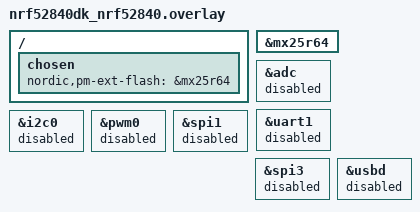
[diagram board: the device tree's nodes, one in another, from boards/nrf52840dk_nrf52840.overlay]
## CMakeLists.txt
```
#
# Copyright (c) 2021 Nordic Semiconductor ASA
#
# SPDX-License-Identifier: LicenseRef-Nordic-5-Clause
#

cmake_minimum_required(VERSION 3.20.0)

find_package(Zephyr REQUIRED HINTS $ENV{ZEPHYR_BASE})
project(matter-lock)

# NORDIC SDK APP START

# Include Data Model and ZAP utils
include(${ZEPHYR_NCS_MATTER_MODULE_DIR}/cmake/sample.cmake)

ncs_get_zap_parent_dir(ZAP_PARENT_DIR)
zephyr_include_directories(${ZAP_PARENT_DIR})

target_include_directories(app PRIVATE
  src
)

target_sources(app PRIVATE
  src/app_task.cpp
  src/bolt_lock_manager.cpp
  src/main.cpp
  src/zcl_callbacks.cpp
)

# Do not treat warnings as errors while the variable may be uninitialized for this sample data model.
# In the door-lock-server implementation, there is a warning that the C++ "optional"
# variable may be uninitialized, but actually, it is wrongly interpreted by the Zephyr toolchain.
target_compile_options(matter-data-model PRIVATE -Wno-error=maybe-uninitialized)

# Without the OpenThread shell and logging, nothing references the OpenThread API objects before
# libCHIP.a is scanned, so symbols used only by Matter's Thread platform stay unresolved. Link the
# OpenThread library again after Matter, so that the linker can resolve them.
if(CONFIG_OPENTHREAD_SOURCES)
  if(CONFIG_OPENTHREAD_FTD)
    set(ot_core_lib openthread-ftd)
  else()
    set(ot_core_lib openthread-mtd)
  endif()
  target_link_libraries(chip INTERFACE
    -Wl,--start-group
    $<TARGET_FILE:${ot_core_lib}>
    -Wl,--end-group
  )
endif()

ncs_configure_data_model()

# NORDIC SDK APP END
```

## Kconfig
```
#
# Copyright (c) 2021 Nordic Semiconductor
#
# SPDX-License-Identifier: LicenseRef-Nordic-5-Clause
#

mainmenu "Matter Lock sample application"

config LOCK_PASS_CREDENTIALS_TO_SET_LOCK_STATE
	bool "Pass used credentials when setting the lock state"
	help
	  This option should stay disabled until TC-DRLK-2.3 is fixed.
	  Related issue: https://github.com/project-chip/connectedhomeip/issues/38222

config STATE_LEDS
	bool "Use LEDs to indicate the device state"
	default y
	help
	  Use LEDs to render the current state of the device such as the progress of commissioning of
	  the device into a network or the factory reset initiation. Note that setting this option to
	  'n' does not disable the LED indicating the state of the simulated bolt.
# Sample configuration used for Thread networking
if OPENTHREAD

choice OPENTHREAD_NORDIC_LIBRARY_CONFIGURATION
	default OPENTHREAD_NORDIC_LIBRARY_MTD
endchoice

choice OPENTHREAD_DEVICE_TYPE
	default OPENTHREAD_MTD
endchoice

choice OPENTHREAD_IMPLEMENTATION
	default OPENTHREAD_SOURCES
endchoice

config CHIP_ENABLE_ICD_SUPPORT
	default y

# Reduce Thread TX output power to 0 dBm for SED device
config OPENTHREAD_DEFAULT_TX_POWER
	default 0

endif # OPENTHREAD

# Increase the storage capacity if the schedules are enabled with secure storage
# This also implies increasing of the OT and Matter stacks because some operations
# performed during commissioning seem to allocate stack buffers based on the
# maximum possible secure asset size.
if DOOR_LOCK_MATTER_ACCESS_SCHEDULES && MATTER_SECURE_STORAGE_BACKEND

config MATTER_SECURE_STORAGE_MAX_ENTRY_NUMBER
	default 128

config TRUSTED_STORAGE_BACKEND_AEAD_MAX_DATA_SIZE
	default 3072

config OPENTHREAD_THREAD_STACK_SIZE
	default 7168

config CHIP_TASK_STACK_SIZE
	default 10240

config MAIN_STACK_SIZE
	default 7168

endif

configdefault HW_UNIQUE_KEY_WRITE_ON_CRYPTO_INIT
	default y

# Keep entries stored by the deprecated Trusted Storage library readable
configdefault SECURE_STORAGE_TRUSTED_STORAGE_COMPATIBILITY
	default y

# The ZMS store implementation supports only 30-bit UIDs
choice SECURE_STORAGE_ITS_STORE_IMPLEMENTATION
	default SECURE_STORAGE_ITS_STORE_IMPLEMENTATION_SETTINGS
endchoice

# Workaround for KRKNWK-20979.
# We must use BT multirole for pairing to work after Matter commissioning.
# TODO: Remove this once the issue is fixed.
choice BT_LL_SOFTDEVICE_VARIANT
	default BT_LL_SOFTDEVICE_MULTIROLE if SOC_SERIES_NRF54L && BT_SMP
endchoice

configdefault CHIP_DEVICE_PRODUCT_FINISH
    default "matte"

configdefault CHIP_DEVICE_PRODUCT_COLOR
    default "navy"

source "$(ZEPHYR_CONNECTEDHOMEIP_MODULE_DIR)/config/nrfconnect/chip-module/Kconfig.features"
source "$(ZEPHYR_CONNECTEDHOMEIP_MODULE_DIR)/config/nrfconnect/chip-module/Kconfig.defaults"
source "Kconfig.zephyr"
```

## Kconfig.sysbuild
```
#
# Copyright (c) 2023 Nordic Semiconductor ASA
#
# SPDX-License-Identifier: LicenseRef-Nordic-5-Clause
#

#### Radio core selection
config NRF_DEFAULT_IPC_RADIO
	default y

# Enable IEEE802.15.4 serialization to network core
# This config automatically pulls in the `overlay-802154.conf` in the ipc_radio image
config NETCORE_IPC_RADIO_IEEE802154
	default y

# Enable Bluetooth serialization to network core
# This config automatically pulls in the `overlay-bt_hci_ipc.conf` in the ipc_radio image
config NETCORE_IPC_RADIO_BT_HCI_IPC
	default y

#### Matter OTA
config MATTER_ADD_ON_OTA
	default n if BOARD_NRF7120DK_NRF7120_CPUAPP
	default y

#### Bootloader
choice BOOTLOADER
	default BOOTLOADER_MCUBOOT if !BOARD_NRF7120DK_NRF7120_CPUAPP
endchoice

if BOOTLOADER_MCUBOOT

#### DFU multi-image support
config DFU_MULTI_IMAGE_PACKAGE_BUILD
	default y

config DFU_MULTI_IMAGE_PACKAGE_APP
	default y

#### DFU network core configuration
if SOC_SERIES_NRF53

choice MCUBOOT_MODE
	default MCUBOOT_MODE_OVERWRITE_ONLY
endchoice

choice BOOT_SIGNATURE_TYPE
	default BOOT_SIGNATURE_TYPE_RSA
endchoice

config SECURE_BOOT_NETCORE
	default y

config NETCORE_APP_UPDATE
	default y

config DFU_MULTI_IMAGE_PACKAGE_NET
	default y

endif # SOC_SERIES_NRF53

endif # BOOTLOADER_MCUBOOT

#### Enable generating factory data
config MATTER_ADD_ON_FACTORY_DATA_GENERATE
	default y

source "share/sysbuild/Kconfig"
```

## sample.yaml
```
sample:
  description: Matter Lock example
  name: Matter Lock
common:
  tags:
    - sysbuild
    - ci_samples_matter
tests:
  sample.matter.lock.debug:
    sysbuild: true
    build_only: true
    tags:
      - dfu_supported
    integration_platforms:
      - nrf54l15dk/nrf54l15/cpuapp
    platform_allow:
      - nrf5340dk/nrf5340/cpuapp
      - nrf54l15dk/nrf54l15/cpuapp
      - nrf54lm20dk/nrf54lm20b/cpuapp
  sample.matter.lock.nrf7120.debug:
    sysbuild: true
    build_only: true
    integration_platforms:
      - nrf7120dk/nrf7120/cpuapp
    platform_allow:
      - nrf7120dk/nrf7120/cpuapp
  sample.matter.lock.release:
    sysbuild: true
    build_only: true
    tags:
      - dfu_supported
    extra_args:
      - FILE_SUFFIX=release
    integration_platforms:
      - nrf5340dk/nrf5340/cpuapp
      - nrf54lm20dk/nrf54lm20b/cpuapp
    platform_allow:
      - nrf5340dk/nrf5340/cpuapp
      - nrf54l15dk/nrf54l15/cpuapp
      - nrf54lm20dk/nrf54lm20b/cpuapp
  sample.matter.lock.smp_dfu:
    sysbuild: true
    build_only: true
    tags:
      - dfu_supported
    extra_args:
      - matter-door-lock-app_SNIPPET="dfu_smp"
    integration_platforms:
      - nrf5340dk/nrf5340/cpuapp
      - nrf54l15dk/nrf54l15/cpuapp
      - nrf54lm20dk/nrf54lm20b/cpuapp
    platform_allow:
      - nrf5340dk/nrf5340/cpuapp
      - nrf54l15dk/nrf54l15/cpuapp
      - nrf54lm20dk/nrf54lm20b/cpuapp
  sample.matter.lock.nus:
    sysbuild: true
    build_only: true
    tags:
      - dfu_supported
    extra_args:
      - matter-door-lock-app_SNIPPET=bt_nus
      - CONFIG_DOOR_LOCK_BLE_MANAGER_AUTH_APP_PASSKEY=112233
    integration_platforms:
      - nrf5340dk/nrf5340/cpuapp
    platform_allow:
      - nrf5340dk/nrf5340/cpuapp
      - nrf54l15dk/nrf54l15/cpuapp
      - nrf54lm20dk/nrf54lm20b/cpuapp
  sample.matter.lock.schedules:
    sysbuild: true
    build_only: true
    tags:
      - dfu_supported
    extra_args:
      - EXTRA_CONF_FILE=schedules.conf
    integration_platforms:
      - nrf5340dk/nrf5340/cpuapp
    platform_allow:
      - nrf5340dk/nrf5340/cpuapp
  sample.matter.lock.release.power_consumption:
    sysbuild: true
    build_only: true
    extra_args:
      - FILE_SUFFIX=release
      - CONFIG_MATTER_LEDS=n
      - CONFIG_MATTER_WATCHDOG=n
      - CONFIG_CHIP_ENABLE_PAIRING_AUTOSTART=y
    integration_platforms:
      - nrf5340dk/nrf5340/cpuapp
    platform_allow:
      - nrf5340dk/nrf5340/cpuapp
      - nrf54l15dk/nrf54l15/cpuapp
      - nrf54lm20dk/nrf54lm20b/cpuapp
```

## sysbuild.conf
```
#
# Copyright (c) 2024 Nordic Semiconductor
#
# SPDX-License-Identifier: LicenseRef-Nordic-5-Clause
#

SB_CONFIG_MATTER_ADD_ON=y

SB_CONFIG_MATTER_ADD_ON_FACTORY_DATA_MERGE_WITH_FIRMWARE=y

SB_CONFIG_MERGED_HEX_FILES=y
```

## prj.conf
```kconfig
#
# Copyright (c) 2022 Nordic Semiconductor ASA
#
# SPDX-License-Identifier: LicenseRef-Nordic-5-Clause
#

# This sample uses Kconfig.defaults to set options common for all
# samples. This file should contain only options specific for this sample
# or overrides of default values.

# Enable CHIP
CONFIG_CHIP=y
CONFIG_CHIP_DEVICE_PRODUCT_NAME="Matter Door Lock"

# Configure ZAP file name
CONFIG_MATTER_ZAP_FILE_PATH="${APPLICATION_CONFIG_DIR}/src/default_zap/lock.zap"

# 32774 == 0x8006 (example lock-app)
CONFIG_CHIP_DEVICE_PRODUCT_ID=32774
CONFIG_STD_CPP17=y

# Enable Matter extended announcement and increase duration to 1 hour.
CONFIG_CHIP_BLE_EXT_ADVERTISING=y
CONFIG_CHIP_BLE_ADVERTISING_DURATION=60

# Add support for LEDs and buttons on Nordic development kits
CONFIG_DK_LIBRARY=y

# Bluetooth Low Energy configuration
CONFIG_BT_DEVICE_NAME="MatterLock"

# Suspend devices when the CPU goes into sleep
CONFIG_PM_DEVICE=y
CONFIG_PM_DEVICE_RUNTIME=y
CONFIG_CHIP_QSPI_NOR_POWER_MANAGEMENT_SUPPORT=n

# Other settings
CONFIG_THREAD_NAME=y
CONFIG_MPU_STACK_GUARD=y
CONFIG_RESET_ON_FATAL_ERROR=n
CONFIG_CHIP_LIB_SHELL=y
CONFIG_MATTER_TEST_SHELL=y

# Reduce application size
CONFIG_USE_SEGGER_RTT=n
CONFIG_MATTER_LOG_LEVEL_INF=y
CONFIG_CHIP_APP_LOG_LEVEL=3

# Enable Factory Data feature
CONFIG_CHIP_FACTORY_DATA=y
CONFIG_CHIP_FACTORY_DATA_BUILD=y

# Enable Matter Access module
CONFIG_DOOR_LOCK_MATTER_ACCESS=y
CONFIG_DOOR_LOCK_MATTER_ACCESS_CREDENTIAL_TYPES_PIN=y

CONFIG_MATTER_ZAP_GENERATION_STATIC=y
CONFIG_SECURE_STORAGE=n
```

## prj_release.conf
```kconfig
#
# Copyright (c) 2022 Nordic Semiconductor ASA
#
# SPDX-License-Identifier: LicenseRef-Nordic-5-Clause
#

# This sample uses Kconfig.defaults to set options common for all
# samples. This file should contain only options specific for this sample
# or overrides of default values.

# Enable CHIP
CONFIG_CHIP=y
CONFIG_CHIP_DEVICE_PRODUCT_NAME="Matter Door Lock"

# Configure ZAP file name
CONFIG_MATTER_ZAP_FILE_PATH="${APPLICATION_CONFIG_DIR}/src/default_zap/lock.zap"

# 32774 == 0x8006 (example lock-app)
CONFIG_CHIP_DEVICE_PRODUCT_ID=32774
CONFIG_STD_CPP17=y

# Enable Matter extended announcement and increase duration to 1 hour.
CONFIG_CHIP_BLE_EXT_ADVERTISING=y
CONFIG_CHIP_BLE_ADVERTISING_DURATION=60

# Add support for LEDs and buttons on Nordic development kits
CONFIG_DK_LIBRARY=y

# Bluetooth Low Energy configuration
CONFIG_BT_DEVICE_NAME="MatterLock"

# Suspend devices when the CPU goes into sleep
CONFIG_PM_DEVICE=y

# Enable system reset on fatal error
CONFIG_RESET_ON_FATAL_ERROR=y

# Try to disable unused RAM blocks to reduce power consumption
CONFIG_RAM_POWER_DOWN_LIBRARY=y

# Disable all debug features
CONFIG_USE_SEGGER_RTT=n
CONFIG_SHELL=n
CONFIG_OPENTHREAD_SHELL=n
CONFIG_CONSOLE=n
CONFIG_UART_CONSOLE=n
CONFIG_SERIAL=n
CONFIG_LOG=n
CONFIG_LOG_MODE_MINIMAL=n
CONFIG_ASSERT_VERBOSE=n
CONFIG_ASSERT_NO_FILE_INFO=y
CONFIG_PRINTK=n
CONFIG_PRINTK_SYNC=n
CONFIG_THREAD_NAME=n
CONFIG_BOOT_BANNER=n
CONFIG_NCS_BOOT_BANNER=n

# Enable Factory Data feature
CONFIG_CHIP_FACTORY_DATA=y
CONFIG_CHIP_FACTORY_DATA_BUILD=y

# Enable Watchdog
CONFIG_MATTER_WATCHDOG=y

# Enable LTO to decrease the flash usage.
CONFIG_LTO=y
CONFIG_ISR_TABLES_LOCAL_DECLARATION=y

# Enable Matter Access module
CONFIG_DOOR_LOCK_MATTER_ACCESS=y
CONFIG_DOOR_LOCK_MATTER_ACCESS_CREDENTIAL_TYPES_PIN=y

CONFIG_MATTER_ZAP_GENERATION_STATIC=y
CONFIG_SECURE_STORAGE=n
```

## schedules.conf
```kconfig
#
# Copyright (c) 2026 Nordic Semiconductor ASA
#
# SPDX-License-Identifier: LicenseRef-Nordic-5-Clause
#

# Switch the zap file path
CONFIG_MATTER_ZAP_FILE_PATH="${APPLICATION_CONFIG_DIR}/src/schedules_zap/lock.zap"

# Enable schedules and read client configuration
CONFIG_DOOR_LOCK_MATTER_ACCESS_SCHEDULES=y
CONFIG_DOOR_LOCK_MATTER_ACCESS_DEBUG=y
CONFIG_CHIP_ENABLE_READ_CLIENT=y
```

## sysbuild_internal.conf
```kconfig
#
# Copyright (c) 2024 Nordic Semiconductor
#
# SPDX-License-Identifier: LicenseRef-Nordic-5-Clause
#

SB_CONFIG_PARTITION_MANAGER=y

SB_CONFIG_MERGED_HEX_FILES=y

# Enable the DFU image compression.
SB_CONFIG_MCUBOOT_MODE_OVERWRITE_ONLY=y
SB_CONFIG_MCUBOOT_COMPRESSED_IMAGE_SUPPORT=y
```

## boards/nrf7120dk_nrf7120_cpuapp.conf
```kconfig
#
# Copyright (c) 2026 Nordic Semiconductor ASA
#
# SPDX-License-Identifier: LicenseRef-Nordic-5-Clause
#

# Wi-Fi
CONFIG_CHIP_WIFI=y
CONFIG_WIFI_NRF71_PATCH=y

# Lower System ON idle current: see lib_nrf71_idle_power. Keep the
# default RAM_RETAIN_FULL tier; RAM_RETAIN_USED_ONLY has been observed
# to cause issues on Wi-Fi builds.
CONFIG_NRF71_IDLE_POWER=y

# TODO: MCUboot is currently not supported on the nRF7120 DK.
CONFIG_CHIP_BOOTLOADER_NONE=y

# TODO: Currently MRAM does not support clearing factory data, so we can not
# migrate the DAC private key
CONFIG_CHIP_CRYPTO_PSA_MIGRATE_DAC_PRIV_KEY=n

# TODO: Enabling low-power mode unconditionally gives BLE more radio time,
# allowing the device to connect to Wi-Fi and send responses over BLE.
CONFIG_NRF_WIFI_LOW_POWER=y
```

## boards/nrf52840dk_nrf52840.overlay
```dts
/*
 * Copyright (c) 2021 Nordic Semiconductor ASA
 *
 * SPDX-License-Identifier: LicenseRef-Nordic-5-Clause
 */

#include <door_lock/common/nrf52840_partitions.dtsi>

/ {
	chosen {
		nordic,pm-ext-flash = &mx25r64;
	};
};

&mx25r64 {
	status = "okay";
};

/* Disable unused peripherals to reduce power consumption */
&adc {
	status = "disabled";
};

&uart1 {
	status = "disabled";
};

&i2c0 {
	status = "disabled";
};

&pwm0 {
	status = "disabled";
};

&spi1 {
	status = "disabled";
};

&spi3 {
	status = "disabled";
};

&usbd {
	status = "disabled";
};
```

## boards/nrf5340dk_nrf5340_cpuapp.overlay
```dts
/*
 * Copyright (c) 2021 Nordic Semiconductor ASA
 *
 * SPDX-License-Identifier: LicenseRef-Nordic-5-Clause
 */

#include <door_lock/common/nrf5340_cpuapp_partitions.dtsi>
#include <zephyr/dt-bindings/ipc_service/static_vrings.h>

/* Set IPC thread priority to the highest value to not collide with other threads. */
&ipc0 {
	zephyr,priority = <0 PRIO_COOP>;
};

/ {
	chosen {
		nordic,pm-ext-flash = &mx25r64;
	};
};

&mx25r64 {
	status = "okay";
};

/* Disable unused peripherals to reduce power consumption */
&adc {
	status = "disabled";
};

&i2c1 {
	status = "disabled";
};

&pwm0 {
	status = "disabled";
};

&spi2 {
	status = "disabled";
};

&usbd {
	status = "disabled";
};
```

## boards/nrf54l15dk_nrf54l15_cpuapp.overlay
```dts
/*
 * Copyright (c) 2024 Nordic Semiconductor ASA
 *
 * SPDX-License-Identifier: LicenseRef-Nordic-5-Clause
 */

#include <door_lock/common/nrf54l15_cpuapp_partitions.dtsi>

/ {
	buttons {
		/delete-node/ button_0;
	};

	leds {
		/delete-node/ led_0;
	};

	aliases {
		/delete-property/ sw0;
		/delete-property/ led0;
		/delete-property/ mcuboot-led0;
		mcuboot-button0 = &button1;

		/* Use watchdog wdt31 as the application watchdog */
		watchdog0 = &wdt31;
	};

	chosen {
		nordic,pm-ext-flash = &mx25r64;
	};
};

&mx25r64 {
	status = "okay";
};

&wdt31 {
	status = "okay";
};
```

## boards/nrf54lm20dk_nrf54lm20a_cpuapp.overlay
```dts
/*
 * Copyright (c) 2025 Nordic Semiconductor ASA
 *
 * SPDX-License-Identifier: LicenseRef-Nordic-5-Clause
 */

#include <door_lock/common/nrf54lm20_cpuapp_partitions.dtsi>

/ {
	chosen {
		nordic,pm-ext-flash = &mx25r64;
	};

	buttons {
		/delete-node/ button_0;
	};

	leds {
		/delete-node/ led_0;
	};

	aliases {
		/delete-property/ sw0;
		/delete-property/ led0;
		/delete-property/ mcuboot-led0;
		mcuboot-button0 = &button1;

		/* Use watchdog wdt31 as the application watchdog */
		watchdog0 = &wdt31;
	};
};

&mx25r64 {
	status = "okay";
};

&wdt31 {
	status = "okay";
};
```

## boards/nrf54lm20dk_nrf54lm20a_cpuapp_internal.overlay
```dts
/*
 * Copyright (c) 2025 Nordic Semiconductor ASA
 *
 * SPDX-License-Identifier: LicenseRef-Nordic-5-Clause
 */

#include <door_lock/common/nrf54lm20_cpuapp_internal_partitions.dtsi>

/ {

	buttons {
		/delete-node/ button_0;
	};

	leds {
		/delete-node/ led_0;
	};

	aliases {
		/delete-property/ sw0;
		/delete-property/ led0;
		/delete-property/ mcuboot-led0;
		mcuboot-button0 = &button1;

		/* Use watchdog wdt31 as the application watchdog */
		watchdog0 = &wdt31;
	};
};

&mx25r64 {
	status = "disabled";
};

&wdt31 {
	status = "okay";
};
```

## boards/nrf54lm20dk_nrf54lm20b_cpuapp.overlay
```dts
/*
 * Copyright (c) 2026 Nordic Semiconductor ASA
 *
 * SPDX-License-Identifier: LicenseRef-Nordic-5-Clause
 */

#include <door_lock/common/nrf54lm20_cpuapp_partitions.dtsi>

/ {
	chosen {
		nordic,pm-ext-flash = &mx25r64;
	};

	buttons {
		/delete-node/ button_0;
	};

	leds {
		/delete-node/ led_0;
	};

	aliases {
		/delete-property/ sw0;
		/delete-property/ led0;
		/delete-property/ mcuboot-led0;
		mcuboot-button0 = &button1;

		/* Use watchdog wdt31 as the application watchdog */
		watchdog0 = &wdt31;
	};
};

&mx25r64 {
	status = "okay";
};

&wdt31 {
	status = "okay";
};
```

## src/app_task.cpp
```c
/*
 * Copyright (c) 2021 Nordic Semiconductor ASA
 *
 * SPDX-License-Identifier: LicenseRef-Nordic-5-Clause
 */

#include "app_task.h"
#include "bolt_lock_manager.h"
#include "clusters/identify.h"

#include "app/matter_init.h"
#include "app/task_executor.h"

#ifdef CONFIG_DOOR_LOCK_DFU_SMP_SERVICE
#include <dfu_smp_service/dfu_smp_service.h>
#endif // CONFIG_DOOR_LOCK_DFU_SMP_SERVICE

#ifdef CONFIG_DOOR_LOCK_NUS_SERVICE
#include <nus_service/nus_service.h>
#endif // CONFIG_DOOR_LOCK_NUS_SERVICE

#include <app-common/zap-generated/attributes/Accessors.h>
#include <app/clusters/door-lock-server/door-lock-server.h>
#include <platform/CHIPDeviceLayer.h>
#include <setup_payload/OnboardingCodesUtil.h>

#include <zephyr/logging/log.h>

LOG_MODULE_DECLARE(app, CONFIG_CHIP_APP_LOG_LEVEL);

using namespace ::chip;
using namespace ::chip::app;
using namespace ::chip::DeviceLayer;

namespace {
constexpr EndpointId kLockEndpointId = 1;

#if defined(CONFIG_DOOR_LOCK_NUS_SERVICE) || defined(CONFIG_DOOR_LOCK_DFU_SMP_SERVICE)

enum class AdvertisingPriority : uint8_t {
	DFU_SMP = CHIP_DEVICE_BLE_ADVERTISING_PRIORITY + 1,
	NUS,
};

constexpr uint16_t kAdvertisingIntervalMin{ 400 };
constexpr uint16_t kAdvertisingIntervalMax{ 500 };

#endif // CONFIG_DOOR_LOCK_NUS_SERVICE || CONFIG_DOOR_LOCK_DFU_SMP_SERVICE

#define APPLICATION_BUTTON_MASK DK_BTN2_MSK
#define DFU_SMP_BUTTON_MASK DK_BTN3_MSK

#ifndef CONFIG_CHIP_FACTORY_RESET_ERASE_SETTINGS
void AppFactoryResetHandler(const ChipDeviceEvent *event, intptr_t /* unused */)
{
	switch (event->Type) {
	case DeviceEventType::kFactoryReset:
		BoltLockMgr().FactoryReset();
		break;
	default:
		break;
	}
}
#endif

Nrf::Matter::IdentifyCluster sIdentifyCluster(kLockEndpointId, false, []() {
	Nrf::PostTask([] { Nrf::GetBoard().GetLED(Nrf::DeviceLeds::LED2).Set(BoltLockMgr().IsLocked()); });
});
} /* namespace */

void AppTask::ButtonEventHandler(Nrf::ButtonState state, Nrf::ButtonMask hasChanged)
{
	if ((APPLICATION_BUTTON_MASK & hasChanged) & state) {
		Nrf::PostTask([] { LockActionEventHandler(); });
	}

#ifdef CONFIG_DOOR_LOCK_DFU_SMP_SERVICE
	if ((DFU_SMP_BUTTON_MASK & hasChanged) & state) {
		Nrf::PostTask([] { DfuSmpActionEventHandler(); });
	}
#endif // CONFIG_DOOR_LOCK_DFU_SMP_SERVICE
}

void AppTask::LockActionEventHandler()
{
	if (BoltLockMgr().IsLocked()) {
		BoltLockMgr().Unlock(BoltLockManager::OperationSource::kButton);
	} else {
		BoltLockMgr().Lock(BoltLockManager::OperationSource::kButton);
	}
}

#ifdef CONFIG_DOOR_LOCK_DFU_SMP_SERVICE
void AppTask::DfuSmpActionEventHandler()
{
	DoorLock::DfuSmpService::Toggle();
}
#endif // CONFIG_DOOR_LOCK_DFU_SMP_SERVICE

void AppTask::LockStateChanged(const BoltLockManager::StateData &stateData)
{
	switch (stateData.mState) {
	case BoltLockManager::State::kLockingInitiated:
		LOG_INF("Lock action initiated");
		Nrf::GetBoard().GetLED(Nrf::DeviceLeds::LED2).Blink(50, 50);
#ifdef CONFIG_DOOR_LOCK_NUS_SERVICE
		DoorLock::NUSService::Send("locking");
#endif // CONFIG_DOOR_LOCK_NUS_SERVICE
		break;
	case BoltLockManager::State::kLockingCompleted:
		LOG_INF("Lock action completed");
		Nrf::GetBoard().GetLED(Nrf::DeviceLeds::LED2).Set(true);
#ifdef CONFIG_DOOR_LOCK_NUS_SERVICE
		DoorLock::NUSService::Send("locked");
#endif // CONFIG_DOOR_LOCK_NUS_SERVICE
		break;
	case BoltLockManager::State::kUnlockingInitiated:
		LOG_INF("Unlock action initiated");
		Nrf::GetBoard().GetLED(Nrf::DeviceLeds::LED2).Blink(50, 50);
#ifdef CONFIG_DOOR_LOCK_NUS_SERVICE
		DoorLock::NUSService::Send("unlocking");
#endif // CONFIG_DOOR_LOCK_NUS_SERVICE
		break;
	case BoltLockManager::State::kUnlockingCompleted:
		LOG_INF("Unlock action completed");
#ifdef CONFIG_DOOR_LOCK_NUS_SERVICE
		DoorLock::NUSService::Send("unlocked");
#endif // CONFIG_DOOR_LOCK_NUS_SERVICE
		Nrf::GetBoard().GetLED(Nrf::DeviceLeds::LED2).Set(false);
		break;
	}

	/* Handle changing attribute state in the application */
	Instance().UpdateClusterState(stateData);
}

void AppTask::UpdateClusterState(const BoltLockManager::StateData &stateData)
{
	BoltLockManager::StateData *stateDataCopy = Platform::New<BoltLockManager::StateData>(stateData);

	if (stateDataCopy == nullptr) {
		LOG_ERR("Failed to allocate memory for BoltLockManager::StateData");
		return;
	}

	CHIP_ERROR err = SystemLayer().ScheduleLambda([stateDataCopy]() {
		UpdateClusterStateHandler(*stateDataCopy);
		Platform::Delete(stateDataCopy);
	});

	if (err != CHIP_NO_ERROR) {
		LOG_ERR("Failed to schedule lambda: %" CHIP_ERROR_FORMAT, err.Format());
		Platform::Delete(stateDataCopy);
	}
}

void AppTask::UpdateClusterStateHandler(const BoltLockManager::StateData &stateData)
{
	using namespace chip::app::Clusters::DoorLock::Attributes;

	DlLockState newLockState;

	switch (stateData.mState) {
	case BoltLockManager::State::kLockingCompleted:
		newLockState = DlLockState::kLocked;
		break;
	case BoltLockManager::State::kUnlockingCompleted:
		newLockState = DlLockState::kUnlocked;
		break;
	default:
		newLockState = DlLockState::kNotFullyLocked;
		break;
	}

	Nullable<DlLockState> currentLockState;
	LockState::Get(kLockEndpointId, currentLockState);

	if (currentLockState.IsNull()) {
		/* Initialize lock state with start value, but not invoke lock/unlock. */
		LockState::Set(kLockEndpointId, newLockState);
	} else {
		LOG_INF("Updating LockState attribute");

		Nullable<uint16_t> userIndex;
		Nullable<List<const LockOpCredentials>> credentials;
#ifdef CONFIG_LOCK_PASS_CREDENTIALS_TO_SET_LOCK_STATE
		List<const LockOpCredentials> credentialList;
#endif

		if (!stateData.mValidateCredentialResult.IsNull()) {
			userIndex = { stateData.mValidateCredentialResult.Value().mUserIndex };

#ifdef CONFIG_LOCK_PASS_CREDENTIALS_TO_SET_LOCK_STATE
			/* `DoorLockServer::SetLockState` exptects list of `LockOpCredentials`,
			   however in case of PIN validation it makes no sense to have more than one
			   credential corresponding to validation result. For simplicity we wrap single
			   credential in list here. */
			credentialList = { &stateData.mValidateCredentialResult.Value().mCredential, 1 };
			credentials = { credentialList };
#endif
		}

		if (!DoorLockServer::Instance().SetLockState(kLockEndpointId, newLockState, stateData.mSource,
							     userIndex, credentials, stateData.mFabricIdx,
							     stateData.mNodeId)) {
			LOG_ERR("Failed to update LockState attribute");
		}
	}
}

#ifdef CONFIG_DOOR_LOCK_NUS_SERVICE
void AppTask::NUSLockCallback(void *context)
{
	LOG_INF("Lock command received");
	if (BoltLockMgr().GetState().mState == BoltLockManager::State::kLockingCompleted ||
	    BoltLockMgr().GetState().mState == BoltLockManager::State::kLockingInitiated) {
		LOG_INF("Device is already locked");
	} else {
		Nrf::PostTask([] { LockActionEventHandler(); });
	}
}

void AppTask::NUSUnlockCallback(void *context)
{
	LOG_INF("Unlock command received");
	if (BoltLockMgr().GetState().mState == BoltLockManager::State::kUnlockingCompleted ||
	    BoltLockMgr().GetState().mState == BoltLockManager::State::kUnlockingInitiated) {
		LOG_INF("Device is already unlocked");
	} else {
		Nrf::PostTask([] { LockActionEventHandler(); });
	}
}
#endif // CONFIG_DOOR_LOCK_NUS_SERVICE

#ifdef CONFIG_MATTER_TEST_EVENT_TRIGGERS
CHIP_ERROR AppTask::DoorLockJammedEventCallback(Nrf::Matter::TestEventTrigger::TriggerValue)
{
	VerifyOrReturnError(DoorLockServer::Instance().SendLockAlarmEvent(kLockEndpointId, AlarmCodeEnum::kLockJammed),
			    CHIP_ERROR_INTERNAL);
	LOG_ERR("Event Trigger: Doorlock jammed.");
	return CHIP_NO_ERROR;
}
#endif

CHIP_ERROR AppTask::Init()
{
	Nrf::Matter::InitData initData{};

#ifdef CONFIG_DOOR_LOCK_DFU_SMP_SERVICE
	initData.mPostServerInitClbk = []() {
		DoorLock::DfuSmpService::Init(to_underlying(AdvertisingPriority::DFU_SMP), kAdvertisingIntervalMin,
					      kAdvertisingIntervalMax);
		DoorLock::DfuSmpService::ConfirmNewImage();
		return CHIP_NO_ERROR;
	};
#endif // CONFIG_DOOR_LOCK_DFU_SMP_SERVICE

	/* Initialize Matter stack */
	ReturnErrorOnFailure(Nrf::Matter::PrepareServer(initData));

	if (!Nrf::GetBoard().Init(ButtonEventHandler)) {
		LOG_ERR("User interface initialization failed.");
		return CHIP_ERROR_INCORRECT_STATE;
	}

	/* Register Matter event handler that controls the connectivity status LED based on the captured Matter network
	 * state. */
	ReturnErrorOnFailure(Nrf::Matter::RegisterEventHandler(Nrf::Board::DefaultMatterEventHandler, 0));

#ifndef CONFIG_CHIP_FACTORY_RESET_ERASE_SETTINGS
	/* Register factory reset event handler.
	 * With this configuration we have to manually clean up the storage,
	 * as whole settings partition won't be erased.
	 * */
	ReturnErrorOnFailure(Nrf::Matter::RegisterEventHandler(AppFactoryResetHandler, 0));
#endif

	/* Initialize lock manager */
	BoltLockMgr().Init(LockStateChanged);

#ifdef CONFIG_DOOR_LOCK_NUS_SERVICE
	int err = DoorLock::NUSService::Init();
	VerifyOrReturnError(err == 0, CHIP_ERROR_INTERNAL, LOG_ERR("Failed to initialize NUS service"));
	DoorLock::NUSService::RegisterCommand("Lock", NUSLockCallback, nullptr);
	DoorLock::NUSService::RegisterCommand("Unlock", NUSUnlockCallback, nullptr);
	err = DoorLock::NUSService::Start(to_underlying(AdvertisingPriority::NUS), kAdvertisingIntervalMin,
					  kAdvertisingIntervalMax);
	VerifyOrReturnError(err == 0, CHIP_ERROR_INTERNAL, LOG_ERR("Failed to start NUS service"));
#endif // CONFIG_DOOR_LOCK_NUS_SERVICE

	/* Register Door Lock test event trigger */
#ifdef CONFIG_MATTER_TEST_EVENT_TRIGGERS
	ReturnErrorOnFailure(Nrf::Matter::TestEventTrigger::Instance().RegisterTestEventTrigger(
		kDoorLockJammedEventTriggerId,
		Nrf::Matter::TestEventTrigger::EventTrigger{ 0, DoorLockJammedEventCallback }));
#endif

	return Nrf::Matter::StartServer();
}

CHIP_ERROR AppTask::StartApp()
{
	ReturnErrorOnFailure(Init());

	while (true) {
		Nrf::DispatchNextTask();
	}

	return CHIP_NO_ERROR;
}
```

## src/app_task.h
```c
/*
 * Copyright (c) 2021 Nordic Semiconductor ASA
 *
 * SPDX-License-Identifier: LicenseRef-Nordic-5-Clause
 */

#pragma once

#include "board/board.h"
#include "board/led_widget.h"
#include "bolt_lock_manager.h"

struct k_timer;
struct Identify;

#ifdef CONFIG_MATTER_TEST_EVENT_TRIGGERS
#include "event_triggers/event_triggers.h"
#endif

class AppTask {
public:
	static AppTask &Instance()
	{
		static AppTask sAppTask;
		return sAppTask;
	};

	CHIP_ERROR StartApp();

	void UpdateClusterState(const BoltLockManager::StateData &stateData);

private:
	CHIP_ERROR Init();

	static void LockActionEventHandler();
#ifdef CONFIG_DOOR_LOCK_DFU_SMP_SERVICE
	static void DfuSmpActionEventHandler();
#endif // CONFIG_DOOR_LOCK_DFU_SMP_SERVICE
	static void ButtonEventHandler(Nrf::ButtonState state, Nrf::ButtonMask hasChanged);
	static void LockStateChanged(const BoltLockManager::StateData &stateData);
	static void UpdateClusterStateHandler(const BoltLockManager::StateData &stateData);

#ifdef CONFIG_DOOR_LOCK_NUS_SERVICE
	static void NUSLockCallback(void *context);
	static void NUSUnlockCallback(void *context);
#endif // CONFIG_DOOR_LOCK_NUS_SERVICE

#ifdef CONFIG_MATTER_TEST_EVENT_TRIGGERS
	constexpr static Nrf::Matter::TestEventTrigger::EventTriggerId kDoorLockJammedEventTriggerId =
		0xFFFF'FFF3'2774'0000;
	static CHIP_ERROR DoorLockJammedEventCallback(Nrf::Matter::TestEventTrigger::TriggerValue);
#endif
};
```

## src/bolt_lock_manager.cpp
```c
/*
 * Copyright (c) 2021 Nordic Semiconductor ASA
 *
 * SPDX-License-Identifier: LicenseRef-Nordic-5-Clause
 */

#include "bolt_lock_manager.h"
#include "app/task_executor.h"

#include "app_task.h"

using namespace chip;

BoltLockManager BoltLockManager::sLock;

void BoltLockManager::Init(StateChangeCallback callback)
{
	mStateChangeCallback = callback;

	k_timer_init(&mActuatorTimer, &BoltLockManager::ActuatorTimerEventHandler, nullptr);
	k_timer_user_data_set(&mActuatorTimer, this);

	AccessMgr::Instance().Init();

	/* Set the default state */
	Nrf::GetBoard().GetLED(Nrf::DeviceLeds::LED2).Set(IsLocked());
}

bool BoltLockManager::GetUser(uint16_t userIndex, EmberAfPluginDoorLockUserInfo &user)
{
	return AccessMgr::Instance().GetUserInfo(userIndex, user);
}

bool BoltLockManager::SetUser(uint16_t userIndex, FabricIndex creator, FabricIndex modifier, const CharSpan &userName,
			      uint32_t uniqueId, UserStatusEnum userStatus, UserTypeEnum userType,
			      CredentialRuleEnum credentialRule, const CredentialStruct *credentials,
			      size_t totalCredentials)
{
	return AccessMgr::Instance().SetUser(userIndex, creator, modifier, userName, uniqueId, userStatus, userType,
					     credentialRule, credentials, totalCredentials);
}

bool BoltLockManager::GetCredential(uint16_t credentialIndex, CredentialTypeEnum credentialType,
				    EmberAfPluginDoorLockCredentialInfo &credential)
{
	return AccessMgr::Instance().GetCredential(credentialIndex, credentialType, credential);
}

bool BoltLockManager::SetCredential(uint16_t credentialIndex, FabricIndex creator, FabricIndex modifier,
				    DlCredentialStatus credentialStatus, CredentialTypeEnum credentialType,
				    const ByteSpan &secret)
{
	return AccessMgr::Instance().SetCredential(credentialIndex, creator, modifier, credentialStatus, credentialType,
						   secret);
}

#ifdef CONFIG_DOOR_LOCK_MATTER_ACCESS_SCHEDULES

DlStatus BoltLockManager::GetWeekDaySchedule(uint8_t weekdayIndex, uint16_t userIndex,
					     EmberAfPluginDoorLockWeekDaySchedule &schedule)
{
	return AccessMgr::Instance().GetWeekDaySchedule(weekdayIndex, userIndex, schedule);
}

DlStatus BoltLockManager::SetWeekDaySchedule(uint8_t weekdayIndex, uint16_t userIndex, DlScheduleStatus status,
					     DaysMaskMap daysMask, uint8_t startHour, uint8_t startMinute,
					     uint8_t endHour, uint8_t endMinute)
{
	return AccessMgr::Instance().SetWeekDaySchedule(weekdayIndex, userIndex, status, daysMask, startHour,
							startMinute, endHour, endMinute);
}

DlStatus BoltLockManager::GetYearDaySchedule(uint8_t yearDayIndex, uint16_t userIndex,
					     EmberAfPluginDoorLockYearDaySchedule &schedule)
{
	return AccessMgr::Instance().GetYearDaySchedule(yearDayIndex, userIndex, schedule);
}

DlStatus BoltLockManager::SetYearDaySchedule(uint8_t yeardayIndex, uint16_t userIndex, DlScheduleStatus status,
					     uint32_t localStartTime, uint32_t localEndTime)
{
	return AccessMgr::Instance().SetYearDaySchedule(yeardayIndex, userIndex, status, localStartTime, localEndTime);
}

DlStatus BoltLockManager::GetHolidaySchedule(uint8_t holidayIndex, EmberAfPluginDoorLockHolidaySchedule &schedule)
{
	return AccessMgr::Instance().GetHolidaySchedule(holidayIndex, schedule);
}

DlStatus BoltLockManager::SetHolidaySchedule(uint8_t holidayIndex, DlScheduleStatus status, uint32_t localStartTime,
					     uint32_t localEndTime, OperatingModeEnum operatingMode)
{
	return AccessMgr::Instance().SetHolidaySchedule(holidayIndex, status, localStartTime, localEndTime,
							operatingMode);
}

#endif /* CONFIG_DOOR_LOCK_MATTER_ACCESS_SCHEDULES */

bool BoltLockManager::ValidateCredential(CredentialTypeEnum credentialType, const chip::ByteSpan &secret,
					 OperationErrorEnum &error, Nullable<ValidateCredentialResult> &result)
{
	return AccessMgr::Instance().ValidateCredential(credentialType, secret, error, result);
}

#ifdef CONFIG_DOOR_LOCK_MATTER_ACCESS_CREDENTIAL_TYPES_PIN

void BoltLockManager::SetRequirePIN(bool require)
{
	return AccessMgr::Instance().SetRequirePIN(require);
}
bool BoltLockManager::GetRequirePIN()
{
	return AccessMgr::Instance().GetRequirePIN();
}

#endif // CONFIG_DOOR_LOCK_MATTER_ACCESS_CREDENTIAL_TYPES_PIN

void BoltLockManager::Lock(const OperationSource source, const Nullable<chip::FabricIndex> &fabricIdx,
			   const Nullable<chip::NodeId> &nodeId,
			   const Nullable<ValidateCredentialResult> &validateCredentialResult)
{
	VerifyOrReturn(mStateData.mState != State::kLockingCompleted);
	StateData newStateData{ State::kLockingInitiated, source, fabricIdx, nodeId, validateCredentialResult };
	SetStateData(newStateData);

	k_timer_start(&mActuatorTimer, K_MSEC(kActuatorMovementTimeMs), K_NO_WAIT);
}

void BoltLockManager::Unlock(const OperationSource source, const Nullable<chip::FabricIndex> &fabricIdx,
			     const Nullable<chip::NodeId> &nodeId,
			     const Nullable<ValidateCredentialResult> &validateCredentialResult)
{
	VerifyOrReturn(mStateData.mState != State::kUnlockingCompleted);
	StateData newStateData{ State::kUnlockingInitiated, source, fabricIdx, nodeId, validateCredentialResult };
	SetStateData(newStateData);

	k_timer_start(&mActuatorTimer, K_MSEC(kActuatorMovementTimeMs), K_NO_WAIT);
}

void BoltLockManager::ActuatorTimerEventHandler(k_timer *timer)
{
	/*
	 * The timer event handler is called in the context of the system clock ISR.
	 * Post an event to the application task queue to process the event in the
	 * context of the application thread.
	 */

	BoltLockManagerEvent event;
	event.manager = static_cast<BoltLockManager *>(k_timer_user_data_get(timer));
	Nrf::PostTask([event] { ActuatorAppEventHandler(event); });
}

void BoltLockManager::ActuatorAppEventHandler(const BoltLockManagerEvent &event)
{
	BoltLockManager *lock = reinterpret_cast<BoltLockManager *>(event.manager);

	switch (lock->mStateData.mState) {
	case State::kLockingInitiated:
		lock->SetState(State::kLockingCompleted);
		break;
	case State::kUnlockingInitiated:
		lock->SetState(State::kUnlockingCompleted);
		break;
	default:
		break;
	}
}

void BoltLockManager::SetState(State state)
{
	mStateData.mState = state;

	if (mStateChangeCallback != nullptr) {
		mStateChangeCallback(mStateData);
	}
}

void BoltLockManager::SetStateData(const StateData &stateData)
{
	mStateData = stateData;

	if (mStateChangeCallback != nullptr) {
		mStateChangeCallback(mStateData);
	}
}

void BoltLockManager::FactoryReset()
{
	AccessMgr::Instance().FactoryReset();
}
```

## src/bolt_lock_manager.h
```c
/*
 * Copyright (c) 2021 Nordic Semiconductor ASA
 *
 * SPDX-License-Identifier: LicenseRef-Nordic-5-Clause
 */

#pragma once

#include <app/clusters/door-lock-server/door-lock-server.h>
#include <lib/core/ClusterEnums.h>
#include <matter_access/access_manager.h>

#include <zephyr/kernel.h>

#include <cstdint>

struct BoltLockManagerEvent;

class BoltLockManager {
	using AccessMgr = DoorLock::MatterAccess::AccessManagerType;

public:
	static constexpr size_t kMaxCredentialLength = 128;

	enum class State : uint8_t {
		kLockingInitiated = 0,
		kLockingCompleted,
		kUnlockingInitiated,
		kUnlockingCompleted,
	};

	struct UserData {
		char mName[DOOR_LOCK_USER_NAME_BUFFER_SIZE];
		CredentialStruct mCredentials[CONFIG_DOOR_LOCK_MATTER_ACCESS_MAX_NUM_CREDENTIALS_PER_USER];
	};

	struct CredentialData {
		chip::Platform::ScopedMemoryBuffer<uint8_t> mSecret;
	};

	using OperationSource = chip::app::Clusters::DoorLock::OperationSourceEnum;
	using ValidateCredentialResult = AccessMgr::ValidateCredentialResult;

	struct StateData {
		State mState;
		OperationSource mSource;
		Nullable<chip::FabricIndex> mFabricIdx;
		Nullable<chip::NodeId> mNodeId;
		Nullable<ValidateCredentialResult> mValidateCredentialResult;
	};

	using StateChangeCallback = void (*)(const StateData &);

	static constexpr uint32_t kActuatorMovementTimeMs = 2000;

	void Init(StateChangeCallback callback);

	const StateData &GetState() const { return mStateData; }
	bool IsLocked() const { return mStateData.mState == State::kLockingCompleted; }

	bool GetUser(uint16_t userIndex, EmberAfPluginDoorLockUserInfo &user);
	bool SetUser(uint16_t userIndex, chip::FabricIndex creator, chip::FabricIndex modifier,
		     const chip::CharSpan &userName, uint32_t uniqueId, UserStatusEnum userStatus,
		     UserTypeEnum userType, CredentialRuleEnum credentialRule, const CredentialStruct *credentials,
		     size_t totalCredentials);

	bool GetCredential(uint16_t credentialIndex, CredentialTypeEnum credentialType,
			   EmberAfPluginDoorLockCredentialInfo &credential);
	bool SetCredential(uint16_t credentialIndex, chip::FabricIndex creator, chip::FabricIndex modifier,
			   DlCredentialStatus credentialStatus, CredentialTypeEnum credentialType,
			   const chip::ByteSpan &secret);

#ifdef CONFIG_DOOR_LOCK_MATTER_ACCESS_SCHEDULES
	DlStatus GetWeekDaySchedule(uint8_t weekdayIndex, uint16_t userIndex,
				    EmberAfPluginDoorLockWeekDaySchedule &schedule);
	DlStatus SetWeekDaySchedule(uint8_t weekdayIndex, uint16_t userIndex, DlScheduleStatus status,
				    DaysMaskMap daysMask, uint8_t startHour, uint8_t startMinute, uint8_t endHour,
				    uint8_t endMinute);
	DlStatus GetYearDaySchedule(uint8_t yearDayIndex, uint16_t userIndex,
				    EmberAfPluginDoorLockYearDaySchedule &schedule);
	DlStatus SetYearDaySchedule(uint8_t yearDayIndex, uint16_t userIndex, DlScheduleStatus status,
				    uint32_t localStartTime, uint32_t localEndTime);
	DlStatus GetHolidaySchedule(uint8_t holidayIndex, EmberAfPluginDoorLockHolidaySchedule &schedule);
	DlStatus SetHolidaySchedule(uint8_t holidayIndex, DlScheduleStatus status, uint32_t localStartTime,
				    uint32_t localEndTime, OperatingModeEnum operatingMode);
#endif /* CONFIG_DOOR_LOCK_MATTER_ACCESS_SCHEDULES */

	bool ValidateCredential(CredentialTypeEnum credentialType, const chip::ByteSpan &secret,
				OperationErrorEnum &error, Nullable<ValidateCredentialResult> &result);

	void Lock(const OperationSource source, const Nullable<chip::FabricIndex> &fabricIdx = NullNullable,
		  const Nullable<chip::NodeId> &nodeId = NullNullable,
		  const Nullable<ValidateCredentialResult> &validateCredentialResult = NullNullable);
	void Unlock(const OperationSource source, const Nullable<chip::FabricIndex> &fabricIdx = NullNullable,
		    const Nullable<chip::NodeId> &nodeId = NullNullable,
		    const Nullable<ValidateCredentialResult> &validateCredentialResult = NullNullable);

#ifdef CONFIG_DOOR_LOCK_MATTER_ACCESS_CREDENTIAL_TYPES_PIN
	void SetRequirePIN(bool require);
	bool GetRequirePIN();
#endif // CONFIG_DOOR_LOCK_MATTER_ACCESS_CREDENTIAL_TYPES_PIN

	void FactoryReset();

private:
	friend class AppTask;

	void SetState(State state);
	void SetStateData(const StateData &stateData);

	static void ActuatorTimerEventHandler(k_timer *timer);
	static void ActuatorAppEventHandler(const BoltLockManagerEvent &event);
	friend BoltLockManager &BoltLockMgr();

	StateData mStateData = { State::kLockingCompleted, OperationSource::kButton, {}, {}, {} };
	StateChangeCallback mStateChangeCallback = nullptr;
	k_timer mActuatorTimer = {};

	static BoltLockManager sLock;
};

inline BoltLockManager &BoltLockMgr()
{
	return BoltLockManager::sLock;
}

struct BoltLockManagerEvent {
	BoltLockManager *manager;
};
```

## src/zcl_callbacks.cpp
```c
/*
 * Copyright (c) 2021 Nordic Semiconductor ASA
 *
 * SPDX-License-Identifier: LicenseRef-Nordic-5-Clause
 */

#include "app_task.h"
#include "bolt_lock_manager.h"

#include <app-common/zap-generated/attributes/Accessors.h>
#include <app-common/zap-generated/ids/Clusters.h>
#include <app/ConcreteAttributePath.h>
#include <app/clusters/door-lock-server/door-lock-server.h>
#include <app/data-model/Nullable.h>
#include <lib/core/DataModelTypes.h>
#include <lib/support/CodeUtils.h>

using namespace ::chip;
using namespace ::chip::app;
using ::chip::app::Clusters::DoorLock::DlLockType;
using ::chip::app::DataModel::Nullable;

void MatterPostAttributeChangeCallback(const chip::app::ConcreteAttributePath &attributePath, uint8_t type,
				       uint16_t size, uint8_t *value)
{
	VerifyOrReturn(attributePath.mClusterId == Clusters::DoorLock::Id);

#ifdef CONFIG_DOOR_LOCK_MATTER_ACCESS_CREDENTIAL_TYPES_PIN
	if (attributePath.mAttributeId == Clusters::DoorLock::Attributes::RequirePINforRemoteOperation::Id) {
		BoltLockMgr().SetRequirePIN(*value);
	}
#endif // CONFIG_DOOR_LOCK_MATTER_ACCESS_CREDENTIAL_TYPES_PIN
}

bool emberAfPluginDoorLockGetUser(EndpointId endpointId, uint16_t userIndex, EmberAfPluginDoorLockUserInfo &user)
{
	return BoltLockMgr().GetUser(userIndex, user);
}

bool emberAfPluginDoorLockSetUser(EndpointId endpointId, uint16_t userIndex, FabricIndex creator, FabricIndex modifier,
				  const CharSpan &userName, uint32_t uniqueId, UserStatusEnum userStatus,
				  UserTypeEnum userType, CredentialRuleEnum credentialRule,
				  const CredentialStruct *credentials, size_t totalCredentials)
{
	return BoltLockMgr().SetUser(userIndex, creator, modifier, userName, uniqueId, userStatus, userType,
				     credentialRule, credentials, totalCredentials);
}

bool emberAfPluginDoorLockGetCredential(EndpointId endpointId, uint16_t credentialIndex,
					CredentialTypeEnum credentialType,
					EmberAfPluginDoorLockCredentialInfo &credential)
{
	return BoltLockMgr().GetCredential(credentialIndex, credentialType, credential);
}

bool emberAfPluginDoorLockSetCredential(EndpointId endpointId, uint16_t credentialIndex, FabricIndex creator,
					FabricIndex modifier, DlCredentialStatus credentialStatus,
					CredentialTypeEnum credentialType, const ByteSpan &secret)
{
	return BoltLockMgr().SetCredential(credentialIndex, creator, modifier, credentialStatus, credentialType,
					   secret);
}

bool emberAfPluginDoorLockOnDoorLockCommand(EndpointId endpointId, const Nullable<chip::FabricIndex> &fabricIdx,
					    const Nullable<chip::NodeId> &nodeId, const Optional<ByteSpan> &pinCode,
					    OperationErrorEnum &err)
{
	Nullable<BoltLockManager::ValidateCredentialResult> validateCredentialResult;
	bool success = true;

	if (pinCode.HasValue()) {
		success = BoltLockMgr().ValidateCredential(CredentialTypeEnum::kPin, pinCode.Value(), err,
							   validateCredentialResult);
	}

	/* Handle changing attribute state on command reception */
	if (success) {
		BoltLockMgr().Lock(BoltLockManager::OperationSource::kRemote, fabricIdx, nodeId,
				   validateCredentialResult);
	}

	return success;
}

bool emberAfPluginDoorLockOnDoorUnlockCommand(EndpointId endpointId, const Nullable<chip::FabricIndex> &fabricIdx,
					      const Nullable<chip::NodeId> &nodeId, const Optional<ByteSpan> &pinCode,
					      OperationErrorEnum &err)
{
	Nullable<BoltLockManager::ValidateCredentialResult> validateCredentialResult;
	bool success = true;

	if (pinCode.HasValue()) {
		success = BoltLockMgr().ValidateCredential(CredentialTypeEnum::kPin, pinCode.Value(), err,
							   validateCredentialResult);
	}

	/* Handle changing attribute state on command reception */
	if (success) {
		BoltLockMgr().Unlock(BoltLockManager::OperationSource::kRemote, fabricIdx, nodeId,
				     validateCredentialResult);
	}

	return success;
}

void emberAfPluginDoorLockOnAutoRelock(chip::EndpointId endpointId)
{
	BoltLockMgr().Lock(BoltLockManager::OperationSource::kAuto);
}

void emberAfDoorLockClusterInitCallback(EndpointId endpoint)
{
	DoorLockServer::Instance().InitServer(endpoint);

	const auto logOnFailure = [](Protocols::InteractionModel::Status status, const char *attributeName) {
		if (status != Protocols::InteractionModel::Status::Success) {
			ChipLogError(Zcl, "Failed to set DoorLock %s: %x", attributeName, to_underlying(status));
		}
	};

	logOnFailure(Clusters::DoorLock::Attributes::LockType::Set(endpoint, DlLockType::kDeadBolt), "type");
	logOnFailure(Clusters::DoorLock::Attributes::NumberOfTotalUsersSupported::Set(
			     endpoint, CONFIG_DOOR_LOCK_MATTER_ACCESS_MAX_NUM_USERS),
		     "number of users");

#ifdef CONFIG_DOOR_LOCK_MATTER_ACCESS_CREDENTIAL_TYPES_PIN
	logOnFailure(Clusters::DoorLock::Attributes::NumberOfPINUsersSupported::Set(
			     endpoint, CONFIG_DOOR_LOCK_MATTER_ACCESS_MAX_NUM_CREDENTIALS_PER_TYPE),
		     "number of PIN users");
#endif // CONFIG_DOOR_LOCK_MATTER_ACCESS_CREDENTIAL_TYPES_PIN
	logOnFailure(Clusters::DoorLock::Attributes::NumberOfCredentialsSupportedPerUser::Set(
			     endpoint, CONFIG_DOOR_LOCK_MATTER_ACCESS_MAX_NUM_CREDENTIALS_PER_USER),
		     "number of credentials per user");
#ifdef CONFIG_DOOR_LOCK_MATTER_ACCESS_CREDENTIAL_TYPES_PIN
	logOnFailure(Clusters::DoorLock::Attributes::RequirePINforRemoteOperation::Set(endpoint,
										       BoltLockMgr().GetRequirePIN()),
		     "require PIN code for the remote operation");
#endif // CONFIG_DOOR_LOCK_MATTER_ACCESS_CREDENTIAL_TYPES_PIN
#ifdef CONFIG_DOOR_LOCK_MATTER_ACCESS_SCHEDULES
	logOnFailure(Clusters::DoorLock::Attributes::NumberOfWeekDaySchedulesSupportedPerUser::Set(
			     endpoint, CONFIG_DOOR_LOCK_MATTER_ACCESS_SCHEDULES_MAX_WEEKDAY_SCHEDULES_PER_USER),
		     "number of WeekDay schedules per user");
	logOnFailure(Clusters::DoorLock::Attributes::NumberOfYearDaySchedulesSupportedPerUser::Set(
			     endpoint, CONFIG_DOOR_LOCK_MATTER_ACCESS_SCHEDULES_MAX_YEARDAY_SCHEDULES_PER_USER),
		     "number of YearDay schedules per user");
	logOnFailure(Clusters::DoorLock::Attributes::NumberOfHolidaySchedulesSupported::Set(
			     endpoint, CONFIG_DOOR_LOCK_MATTER_ACCESS_SCHEDULES_MAX_HOLIDAY_SCHEDULES),
		     "number of holiday schedules");
#endif /* CONFIG_DOOR_LOCK_MATTER_ACCESS_SCHEDULES */

	BoltLockManager::StateData state = BoltLockMgr().GetState();
	state.mSource = BoltLockManager::OperationSource::kUnspecified;
	AppTask::Instance().UpdateClusterState(state);
}

#ifdef CONFIG_DOOR_LOCK_MATTER_ACCESS_SCHEDULES

DlStatus emberAfPluginDoorLockGetSchedule(chip::EndpointId endpointId, uint8_t weekdayIndex, uint16_t userIndex,
					  EmberAfPluginDoorLockWeekDaySchedule &schedule)
{
	return BoltLockMgr().GetWeekDaySchedule(weekdayIndex, userIndex, schedule);
}

DlStatus emberAfPluginDoorLockGetSchedule(chip::EndpointId endpointId, uint8_t yearDayIndex, uint16_t userIndex,
					  EmberAfPluginDoorLockYearDaySchedule &schedule)
{
	return BoltLockMgr().GetYearDaySchedule(yearDayIndex, userIndex, schedule);
}

DlStatus emberAfPluginDoorLockGetSchedule(chip::EndpointId endpointId, uint8_t holidayIndex,
					  EmberAfPluginDoorLockHolidaySchedule &holidaySchedule)
{
	return BoltLockMgr().GetHolidaySchedule(holidayIndex, holidaySchedule);
}

DlStatus emberAfPluginDoorLockSetSchedule(chip::EndpointId endpointId, uint8_t weekdayIndex, uint16_t userIndex,
					  DlScheduleStatus status, DaysMaskMap daysMask, uint8_t startHour,
					  uint8_t startMinute, uint8_t endHour, uint8_t endMinute)
{
	return BoltLockMgr().SetWeekDaySchedule(weekdayIndex, userIndex, status, daysMask, startHour, startMinute,
						endHour, endMinute);
}

DlStatus emberAfPluginDoorLockSetSchedule(chip::EndpointId endpointId, uint8_t yearDayIndex, uint16_t userIndex,
					  DlScheduleStatus status, uint32_t localStartTime, uint32_t localEndTime)
{
	return BoltLockMgr().SetYearDaySchedule(yearDayIndex, userIndex, status, localStartTime, localEndTime);
}

DlStatus emberAfPluginDoorLockSetSchedule(chip::EndpointId endpointId, uint8_t holidayIndex, DlScheduleStatus status,
					  uint32_t localStartTime, uint32_t localEndTime,
					  OperatingModeEnum operatingMode)
{
	return BoltLockMgr().SetHolidaySchedule(holidayIndex, status, localStartTime, localEndTime, operatingMode);
}

#endif /* CONFIG_DOOR_LOCK_MATTER_ACCESS_SCHEDULES */
```
